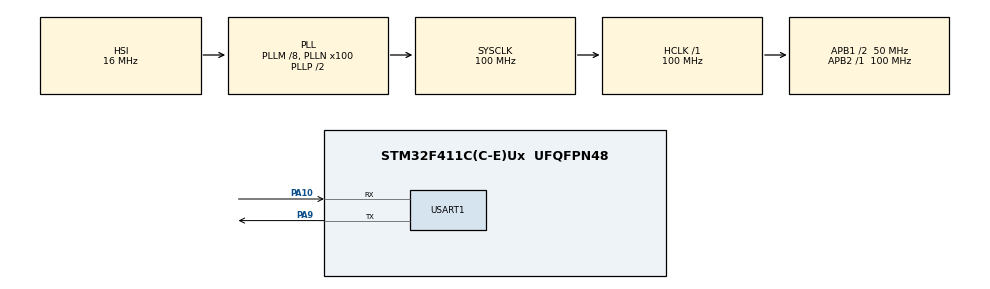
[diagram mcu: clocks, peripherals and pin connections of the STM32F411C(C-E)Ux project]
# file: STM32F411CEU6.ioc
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Mcu.Family=STM32F4
Mcu.Name=STM32F411C(C-E)Ux
Mcu.Package=UFQFPN48
NVIC.PriorityGroup=NVIC_PRIORITYGROUP_4
PA10.Mode=Asynchronous
PA10.Signal=USART1_RX
PA9.Mode=Asynchronous
PA9.Signal=USART1_TX
PC14-OSC32_IN.Mode=LSE-External-Oscillator
PC14-OSC32_IN.Signal=RCC_OSC32_IN
PC15-OSC32_OUT.Mode=LSE-External-Oscillator
PC15-OSC32_OUT.Signal=RCC_OSC32_OUT
PH0\ -\ OSC_IN.Mode=HSE-External-Oscillator
PH0\ -\ OSC_IN.Signal=RCC_OSC_IN
PH1\ -\ OSC_OUT.Mode=HSE-External-Oscillator
PH1\ -\ OSC_OUT.Signal=RCC_OSC_OUT
ProjectManager.HeapSize=0x200
ProjectManager.StackSize=0x400
ProjectManager.TargetToolchain=MDK-ARM V5.32
RCC.48MHZClocksFreq_Value=50000000
RCC.AHBFreq_Value=100000000
RCC.APB1CLKDivider=RCC_HCLK_DIV2
RCC.APB1Freq_Value=50000000
RCC.APB1TimFreq_Value=100000000
RCC.APB2Freq_Value=100000000
RCC.APB2TimFreq_Value=100000000
RCC.CortexFreq_Value=100000000
RCC.HCLKFreq_Value=100000000
RCC.HSE_VALUE=25000000
RCC.HSI_VALUE=16000000
RCC.PLLM=8
RCC.PLLN=100
RCC.SYSCLKFreq_VALUE=100000000
RCC.SYSCLKSource=RCC_SYSCLKSOURCE_PLLCLK
RCC.VCOOutputFreq_Value=200000000
USART1.VirtualMode=VM_ASYNC
board=custom

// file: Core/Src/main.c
/* USER CODE BEGIN Header */
/**
  ******************************************************************************
  * @file           : main.c
  * @brief          : Main program body
  ******************************************************************************
  * @attention
  *
  * Copyright (c) 2026 STMicroelectronics.
  * All rights reserved.
  *
  * This software is licensed under terms that can be found in the LICENSE file
  * in the root directory of this software component.
  * If no LICENSE file comes with this software, it is provided AS-IS.
  *
  ******************************************************************************
  */
/* USER CODE END Header */
#include "main.h"
#include "usart.h"
#include "gpio.h"

/* USER CODE BEGIN Includes */
#include <stdio.h>       /* C 标准库 */

#include "SEGGER_RTT.h"  /* 中间件层：RTT 输出 */

#include "debug.h"       /* 用户中间件层：日志初始化 */

#include "call_stack_demo.h"  /* 用户应用层：函数调用栈演示 */
/* USER CODE END Includes */

void SystemClock_Config(void);

/* USER CODE BEGIN 0 */
#define TAG "main"  /* 当前应用入口的日志标签 */

/* USER CODE END 0 */

int main(void)
{

  /* MCU Configuration--------------------------------------------------------*/

  /* Reset of all peripherals, Initializes the Flash interface and the Systick. */
  HAL_Init();

  /* USER CODE BEGIN Init */
  debug_init();
  /* USER CODE END Init */

  /* Configure the system clock */
  SystemClock_Config();

  /* Initialize all configured peripherals */
  MX_GPIO_Init();
  MX_USART1_UART_Init();
  /* USER CODE BEGIN 2 */
    /* main 局部标记：进入调用链前为 0x12345678。 */
    volatile uint32_t main_stack_marker = 0x12345678U;

    /* 初始化完成后执行一次三级嵌套调用。 */
    CallStackDemo_EnterLevel1(main_stack_marker, 0xA123U);

    /* 到达此处表示调用链已经返回，更新 main 的局部标记。 */
    main_stack_marker = 0x00456789U;
  /* USER CODE END 2 */

  /* Infinite loop */
  while (1)
  {

    /* USER CODE BEGIN 3 */
    /* 周期输出保留的串口、RTT 和 EasyLogger 调试消息。 */
    printf("\r\nTEST 1142!\r\n");
    SEGGER_RTT_printf(0, "Hello,SEGGER RTT!\r\n");
    elog_i(TAG, "elog TEST!\r\n");

    HAL_Delay(2000);
  }
  /* USER CODE END 3 */
}

void SystemClock_Config(void)
{
  RCC_OscInitTypeDef RCC_OscInitStruct = {0};
  RCC_ClkInitTypeDef RCC_ClkInitStruct = {0};

  /** Configure the main internal regulator output voltage
  */
  __HAL_RCC_PWR_CLK_ENABLE();
  __HAL_PWR_VOLTAGESCALING_CONFIG(PWR_REGULATOR_VOLTAGE_SCALE1);

  /** Initializes the RCC Oscillators according to the specified parameters
  * in the RCC_OscInitTypeDef structure.
  */
  RCC_OscInitStruct.OscillatorType = RCC_OSCILLATORTYPE_HSI;
  RCC_OscInitStruct.HSIState = RCC_HSI_ON;
  RCC_OscInitStruct.HSICalibrationValue = RCC_HSICALIBRATION_DEFAULT;
  RCC_OscInitStruct.PLL.PLLState = RCC_PLL_ON;
  RCC_OscInitStruct.PLL.PLLSource = RCC_PLLSOURCE_HSI;
  RCC_OscInitStruct.PLL.PLLM = 8;
  RCC_OscInitStruct.PLL.PLLN = 100;
  RCC_OscInitStruct.PLL.PLLP = RCC_PLLP_DIV2;
  RCC_OscInitStruct.PLL.PLLQ = 4;
  if (HAL_RCC_OscConfig(&RCC_OscInitStruct) != HAL_OK)
  {
    Error_Handler();
  }

  /** Initializes the CPU, AHB and APB buses clocks
  */
  RCC_ClkInitStruct.ClockType = RCC_CLOCKTYPE_HCLK|RCC_CLOCKTYPE_SYSCLK
                              |RCC_CLOCKTYPE_PCLK1|RCC_CLOCKTYPE_PCLK2;
  RCC_ClkInitStruct.SYSCLKSource = RCC_SYSCLKSOURCE_PLLCLK;
  RCC_ClkInitStruct.AHBCLKDivider = RCC_SYSCLK_DIV1;
  RCC_ClkInitStruct.APB1CLKDivider = RCC_HCLK_DIV2;
  RCC_ClkInitStruct.APB2CLKDivider = RCC_HCLK_DIV1;

  if (HAL_RCC_ClockConfig(&RCC_ClkInitStruct, FLASH_LATENCY_3) != HAL_OK)
  {
    Error_Handler();
  }
}

void Error_Handler(void)
{
  __disable_irq();
  while (1)
  {
  }
}
